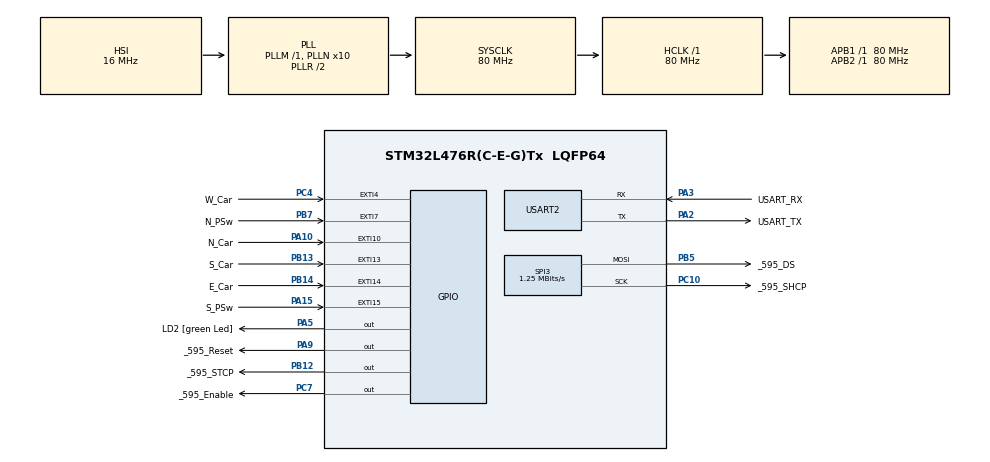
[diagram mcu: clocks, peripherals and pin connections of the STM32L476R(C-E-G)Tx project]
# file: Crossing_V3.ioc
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Mcu.Family=STM32L4
Mcu.Name=STM32L476R(C-E-G)Tx
Mcu.Package=LQFP64
NVIC.EXTI15_10_IRQn=true\:1\:0\:true\:false\:true\:true\:true\:true
NVIC.EXTI4_IRQn=true\:1\:0\:true\:false\:true\:true\:true\:true
NVIC.EXTI9_5_IRQn=true\:1\:0\:true\:false\:true\:true\:true\:true
NVIC.PriorityGroup=NVIC_PRIORITYGROUP_4
PA10.GPIO_Label=N_Car
PA10.GPIO_ModeDefaultEXTI=GPIO_MODE_IT_RISING_FALLING
PA10.Signal=GPXTI10
PA13\ (JTMS-SWDIO).GPIO_Label=TMS
PA13\ (JTMS-SWDIO).Mode=Serial_Wire
PA13\ (JTMS-SWDIO).Signal=SYS_JTMS-SWDIO
PA14\ (JTCK-SWCLK).GPIO_Label=TCK
PA14\ (JTCK-SWCLK).Mode=Serial_Wire
PA14\ (JTCK-SWCLK).Signal=SYS_JTCK-SWCLK
PA15\ (JTDI).GPIO_Label=S_PSw
PA15\ (JTDI).GPIO_PuPd=GPIO_PULLUP
PA15\ (JTDI).Signal=GPXTI15
PA2.GPIO_Label=USART_TX
PA2.GPIO_Mode=GPIO_MODE_AF_PP
PA2.GPIO_PuPd=GPIO_NOPULL
PA2.GPIO_Speed=GPIO_SPEED_FREQ_VERY_HIGH
PA2.Mode=Asynchronous
PA2.Signal=USART2_TX
PA3.GPIO_Label=USART_RX
PA3.GPIO_Mode=GPIO_MODE_AF_PP
PA3.GPIO_PuPd=GPIO_NOPULL
PA3.GPIO_Speed=GPIO_SPEED_FREQ_VERY_HIGH
PA3.Mode=Asynchronous
PA3.Signal=USART2_RX
PA5.GPIO_Label=LD2 [green Led]
PA5.GPIO_ModeDefaultOutputPP=GPIO_MODE_OUTPUT_PP
PA5.GPIO_PuPd=GPIO_NOPULL
PA5.GPIO_Speed=GPIO_SPEED_FREQ_LOW
PA5.Signal=GPIO_Output
PA9.GPIO_Label=_595_Reset
PA9.Signal=GPIO_Output
PB12.GPIO_Label=_595_STCP
PB12.Signal=GPIO_Output
PB13.GPIO_Label=S_Car
PB13.GPIO_ModeDefaultEXTI=GPIO_MODE_IT_RISING_FALLING
PB13.Signal=GPXTI13
PB14.GPIO_Label=E_Car
PB14.GPIO_ModeDefaultEXTI=GPIO_MODE_IT_RISING_FALLING
PB14.Signal=GPXTI14
PB3\ (JTDO-TRACESWO).GPIO_Label=SWO
PB3\ (JTDO-TRACESWO).Signal=SYS_JTDO-SWO
PB5.GPIO_Label=_595_DS
PB5.Mode=TX_Only_Simplex_Unidirect_Master
PB5.Signal=SPI3_MOSI
PB7.GPIO_Label=N_PSw
PB7.GPIO_PuPd=GPIO_PULLUP
PB7.Signal=GPXTI7
PC10.GPIO_Label=_595_SHCP
PC10.Mode=TX_Only_Simplex_Unidirect_Master
PC10.Signal=SPI3_SCK
PC14-OSC32_IN\ (PC14).Mode=LSE-External-Oscillator
PC14-OSC32_IN\ (PC14).Signal=RCC_OSC32_IN
PC15-OSC32_OUT\ (PC15).Mode=LSE-External-Oscillator
PC15-OSC32_OUT\ (PC15).Signal=RCC_OSC32_OUT
PC4.GPIO_Label=W_Car
PC4.GPIO_ModeDefaultEXTI=GPIO_MODE_IT_RISING_FALLING
PC4.Signal=GPXTI4
PC7.GPIO_Label=_595_Enable
PC7.Signal=GPIO_Output
PH0-OSC_IN\ (PH0).Mode=HSE-External-Clock-Source
PH0-OSC_IN\ (PH0).Signal=RCC_OSC_IN
PH1-OSC_OUT\ (PH1).Signal=RCC_OSC_OUT
ProjectManager.HeapSize=0x200
ProjectManager.StackSize=0x400
ProjectManager.TargetToolchain=STM32CubeIDE
RCC.ADCFreq_Value=64000000
RCC.AHBFreq_Value=80000000
RCC.APB1Freq_Value=80000000
RCC.APB1TimFreq_Value=80000000
RCC.APB2Freq_Value=80000000
RCC.APB2TimFreq_Value=80000000
RCC.CortexFreq_Value=80000000
RCC.HCLKFreq_Value=80000000
RCC.HSE_VALUE=8000000
RCC.HSI_VALUE=16000000
RCC.MSI_VALUE=4000000
RCC.PLLN=10
RCC.PLLSourceVirtual=RCC_PLLSOURCE_HSI
RCC.SYSCLKFreq_VALUE=80000000
RCC.SYSCLKSource=RCC_SYSCLKSOURCE_PLLCLK
RCC.USBFreq_Value=64000000
RCC.VCOOutputFreq_Value=160000000
SPI3.BaudRatePrescaler=SPI_BAUDRATEPRESCALER_64
SPI3.CalculateBaudRate=1.25 MBits/s
SPI3.DataSize=SPI_DATASIZE_8BIT
SPI3.Direction=SPI_DIRECTION_2LINES
SPI3.Mode=SPI_MODE_MASTER
SPI3.VirtualType=VM_MASTER
USART2.VirtualMode-Asynchronous=VM_ASYNC
board=NUCLEO-L476RG

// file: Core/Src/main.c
/* USER CODE BEGIN Header */
/**
  ******************************************************************************
  * @file           : main.c
  * @brief          : Main program body
  ******************************************************************************
  * @attention
  *
  * Copyright (c) 2022 STMicroelectronics.
  * All rights reserved.
  *
  * This software is licensed under terms that can be found in the LICENSE file
  * in the root directory of this software component.
  * If no LICENSE file comes with this software, it is provided AS-IS.
  *
  ******************************************************************************
  */
/* USER CODE END Header */
#include "crossing_functions.h"
#include "main.h"

/* USER CODE BEGIN Includes */
#include "stateMachine.h"
#include "gpio_functions.h"
#include "test.h"

/* USER CODE END Includes */

/* USER CODE BEGIN PD */

#undef RUN_TEST_PROGRAM
//#define RUN_TEST_PROGRAM

/* USER CODE END PD */

SPI_HandleTypeDef hspi3;
UART_HandleTypeDef huart2;

void SystemClock_Config(void);
static void MX_GPIO_Init(void);
static void MX_USART2_UART_Init(void);
static void MX_SPI3_Init(void);

/* USER CODE BEGIN 0 */
#ifdef RUN_TEST_PROGRAM
extern void initialise_monitor_handles(void);
#endif
/* USER CODE END 0 */

int main(void)
{

  /* MCU Configuration--------------------------------------------------------*/

  /* Reset of all peripherals, Initializes the Flash interface and the Systick. */
  HAL_Init();

  /* Configure the system clock */
  SystemClock_Config();

  /* Initialize all configured peripherals */
  MX_GPIO_Init();
  MX_USART2_UART_Init();
  MX_SPI3_Init();
  /* USER CODE BEGIN 2 */

#ifdef RUN_TEST_PROGRAM
	testing();
#else
  stateCrossroad();
#endif
  /* USER CODE END 2 */

  /* Infinite loop */
  while (1)
  {

  }
}

void SystemClock_Config(void)
{
  RCC_OscInitTypeDef RCC_OscInitStruct = {0};
  RCC_ClkInitTypeDef RCC_ClkInitStruct = {0};

  /** Configure the main internal regulator output voltage
  */
  if (HAL_PWREx_ControlVoltageScaling(PWR_REGULATOR_VOLTAGE_SCALE1) != HAL_OK)
  {
    Error_Handler();
  }

  /** Initializes the RCC Oscillators according to the specified parameters
  * in the RCC_OscInitTypeDef structure.
  */
  RCC_OscInitStruct.OscillatorType = RCC_OSCILLATORTYPE_HSI;
  RCC_OscInitStruct.HSIState = RCC_HSI_ON;
  RCC_OscInitStruct.HSICalibrationValue = RCC_HSICALIBRATION_DEFAULT;
  RCC_OscInitStruct.PLL.PLLState = RCC_PLL_ON;
  RCC_OscInitStruct.PLL.PLLSource = RCC_PLLSOURCE_HSI;
  RCC_OscInitStruct.PLL.PLLM = 1;
  RCC_OscInitStruct.PLL.PLLN = 10;
  RCC_OscInitStruct.PLL.PLLP = RCC_PLLP_DIV7;
  RCC_OscInitStruct.PLL.PLLQ = RCC_PLLQ_DIV2;
  RCC_OscInitStruct.PLL.PLLR = RCC_PLLR_DIV2;
  if (HAL_RCC_OscConfig(&RCC_OscInitStruct) != HAL_OK)
  {
    Error_Handler();
  }

  /** Initializes the CPU, AHB and APB buses clocks
  */
  RCC_ClkInitStruct.ClockType = RCC_CLOCKTYPE_HCLK|RCC_CLOCKTYPE_SYSCLK
                              |RCC_CLOCKTYPE_PCLK1|RCC_CLOCKTYPE_PCLK2;
  RCC_ClkInitStruct.SYSCLKSource = RCC_SYSCLKSOURCE_PLLCLK;
  RCC_ClkInitStruct.AHBCLKDivider = RCC_SYSCLK_DIV1;
  RCC_ClkInitStruct.APB1CLKDivider = RCC_HCLK_DIV1;
  RCC_ClkInitStruct.APB2CLKDivider = RCC_HCLK_DIV1;

  if (HAL_RCC_ClockConfig(&RCC_ClkInitStruct, FLASH_LATENCY_4) != HAL_OK)
  {
    Error_Handler();
  }
}

static void MX_SPI3_Init(void)
{

  /* SPI3 parameter configuration*/
  hspi3.Instance = SPI3;
  hspi3.Init.Mode = SPI_MODE_MASTER;
  hspi3.Init.Direction = SPI_DIRECTION_2LINES;
  hspi3.Init.DataSize = SPI_DATASIZE_8BIT;
  hspi3.Init.CLKPolarity = SPI_POLARITY_LOW;
  hspi3.Init.CLKPhase = SPI_PHASE_1EDGE;
  hspi3.Init.NSS = SPI_NSS_SOFT;
  hspi3.Init.BaudRatePrescaler = SPI_BAUDRATEPRESCALER_64;
  hspi3.Init.FirstBit = SPI_FIRSTBIT_MSB;
  hspi3.Init.TIMode = SPI_TIMODE_DISABLE;
  hspi3.Init.CRCCalculation = SPI_CRCCALCULATION_DISABLE;
  hspi3.Init.CRCPolynomial = 7;
  hspi3.Init.CRCLength = SPI_CRC_LENGTH_DATASIZE;
  hspi3.Init.NSSPMode = SPI_NSS_PULSE_ENABLE;
  if (HAL_SPI_Init(&hspi3) != HAL_OK)
  {
    Error_Handler();
  }

}

static void MX_USART2_UART_Init(void)
{

  huart2.Instance = USART2;
  huart2.Init.BaudRate = 115200;
  huart2.Init.WordLength = UART_WORDLENGTH_8B;
  huart2.Init.StopBits = UART_STOPBITS_1;
  huart2.Init.Parity = UART_PARITY_NONE;
  huart2.Init.Mode = UART_MODE_TX_RX;
  huart2.Init.HwFlowCtl = UART_HWCONTROL_NONE;
  huart2.Init.OverSampling = UART_OVERSAMPLING_16;
  huart2.Init.OneBitSampling = UART_ONE_BIT_SAMPLE_DISABLE;
  huart2.AdvancedInit.AdvFeatureInit = UART_ADVFEATURE_NO_INIT;
  if (HAL_UART_Init(&huart2) != HAL_OK)
  {
    Error_Handler();
  }

}

static void MX_GPIO_Init(void)
{
  GPIO_InitTypeDef GPIO_InitStruct = {0};

  /* GPIO Ports Clock Enable */
  __HAL_RCC_GPIOC_CLK_ENABLE();
  __HAL_RCC_GPIOH_CLK_ENABLE();
  __HAL_RCC_GPIOA_CLK_ENABLE();
  __HAL_RCC_GPIOB_CLK_ENABLE();

  /*Configure GPIO pin Output Level */
  HAL_GPIO_WritePin(GPIOA, LD2_Pin|_595_Reset_Pin, GPIO_PIN_RESET);

  /*Configure GPIO pin Output Level */
  HAL_GPIO_WritePin(_595_STCP_GPIO_Port, _595_STCP_Pin, GPIO_PIN_RESET);

  /*Configure GPIO pin Output Level */
  HAL_GPIO_WritePin(_595_Enable_GPIO_Port, _595_Enable_Pin, GPIO_PIN_RESET);

  /*Configure GPIO pins : LD2_Pin _595_Reset_Pin */
  GPIO_InitStruct.Pin = LD2_Pin|_595_Reset_Pin;
  GPIO_InitStruct.Mode = GPIO_MODE_OUTPUT_PP;
  GPIO_InitStruct.Pull = GPIO_NOPULL;
  GPIO_InitStruct.Speed = GPIO_SPEED_FREQ_LOW;
  HAL_GPIO_Init(GPIOA, &GPIO_InitStruct);

  /*Configure GPIO pin : W_Car_Pin */
  GPIO_InitStruct.Pin = W_Car_Pin;
  GPIO_InitStruct.Mode = GPIO_MODE_IT_RISING_FALLING;
  GPIO_InitStruct.Pull = GPIO_NOPULL;
  HAL_GPIO_Init(W_Car_GPIO_Port, &GPIO_InitStruct);

  /*Configure GPIO pin : _595_STCP_Pin */
  GPIO_InitStruct.Pin = _595_STCP_Pin;
  GPIO_InitStruct.Mode = GPIO_MODE_OUTPUT_PP;
  GPIO_InitStruct.Pull = GPIO_NOPULL;
  GPIO_InitStruct.Speed = GPIO_SPEED_FREQ_LOW;
  HAL_GPIO_Init(_595_STCP_GPIO_Port, &GPIO_InitStruct);

  /*Configure GPIO pins : S_Car_Pin E_Car_Pin */
  GPIO_InitStruct.Pin = S_Car_Pin|E_Car_Pin;
  GPIO_InitStruct.Mode = GPIO_MODE_IT_RISING_FALLING;
  GPIO_InitStruct.Pull = GPIO_NOPULL;
  HAL_GPIO_Init(GPIOB, &GPIO_InitStruct);

  /*Configure GPIO pin : _595_Enable_Pin */
  GPIO_InitStruct.Pin = _595_Enable_Pin;
  GPIO_InitStruct.Mode = GPIO_MODE_OUTPUT_PP;
  GPIO_InitStruct.Pull = GPIO_NOPULL;
  GPIO_InitStruct.Speed = GPIO_SPEED_FREQ_LOW;
  HAL_GPIO_Init(_595_Enable_GPIO_Port, &GPIO_InitStruct);

  /*Configure GPIO pin : N_Car_Pin */
  GPIO_InitStruct.Pin = N_Car_Pin;
  GPIO_InitStruct.Mode = GPIO_MODE_IT_RISING_FALLING;
  GPIO_InitStruct.Pull = GPIO_NOPULL;
  HAL_GPIO_Init(N_Car_GPIO_Port, &GPIO_InitStruct);

  /*Configure GPIO pin : S_PSw_Pin */
  GPIO_InitStruct.Pin = S_PSw_Pin;
  GPIO_InitStruct.Mode = GPIO_MODE_IT_RISING;
  GPIO_InitStruct.Pull = GPIO_PULLUP;
  HAL_GPIO_Init(S_PSw_GPIO_Port, &GPIO_InitStruct);

  /*Configure GPIO pin : N_PSw_Pin */
  GPIO_InitStruct.Pin = N_PSw_Pin;
  GPIO_InitStruct.Mode = GPIO_MODE_IT_RISING;
  GPIO_InitStruct.Pull = GPIO_PULLUP;
  HAL_GPIO_Init(N_PSw_GPIO_Port, &GPIO_InitStruct);

  /* EXTI interrupt init*/
  HAL_NVIC_SetPriority(EXTI4_IRQn, 1, 0);
  HAL_NVIC_EnableIRQ(EXTI4_IRQn);

  HAL_NVIC_SetPriority(EXTI9_5_IRQn, 1, 0);
  HAL_NVIC_EnableIRQ(EXTI9_5_IRQn);

  HAL_NVIC_SetPriority(EXTI15_10_IRQn, 1, 0);
  HAL_NVIC_EnableIRQ(EXTI15_10_IRQn);

}

void Error_Handler(void)
{
  __disable_irq();
  while (1)
  {
  }
}
